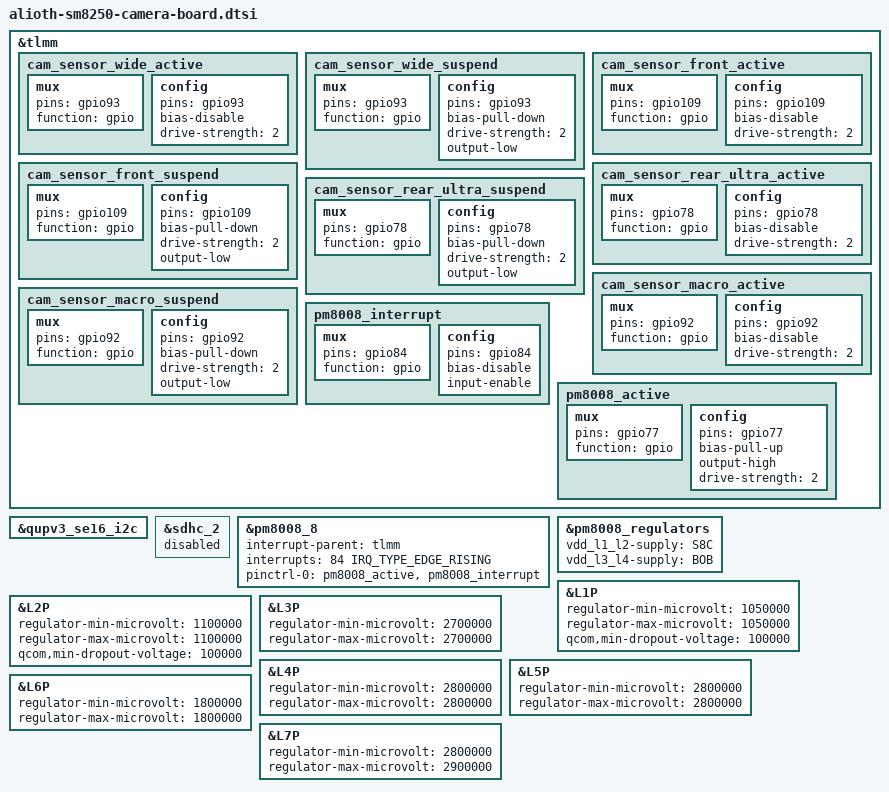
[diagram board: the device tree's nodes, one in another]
&tlmm {
	cam_sensor_wide_active: cam_sensor_wide_active {
		/* RESET WIDE */
		mux {
			pins = "gpio93";
			function = "gpio";
		};

		config {
			pins = "gpio93";
			bias-disable; /* No PULL */
			drive-strength = <2>; /* 2 MA */
		};
	};
	cam_sensor_wide_suspend: cam_sensor_wide_suspend {
		mux {
			pins = "gpio93";
			function = "gpio";
		};

		config {
			pins = "gpio93";
			bias-pull-down; /* PULL DOWN */
			drive-strength = <2>; /* 2 MA */
			output-low;
		};
	};
	cam_sensor_front_active: cam_sensor_front_active {
		/* RESET FRONT */
		mux {
			pins = "gpio109";
			function = "gpio";
		};

		config {
			pins = "gpio109";
			bias-disable; /* No PULL */
			drive-strength = <2>; /* 2 MA */
		};
	};
	cam_sensor_front_suspend: cam_sensor_front_suspend {
		mux {
			pins = "gpio109";
			function = "gpio";
		};

		config {
			pins = "gpio109";
			bias-pull-down; /* PULL DOWN */
			drive-strength = <2>; /* 2 MA */
			output-low;
		};
	};
	cam_sensor_rear_ultra_active: cam_sensor_rear_ultra_active {
		/* RESET REAR ULTRA */
		mux {
			pins = "gpio78";
			function = "gpio";
		};

		config {
			pins = "gpio78";
			bias-disable; /* No PULL */
			drive-strength = <2>; /* 2 MA */
		};
	};
	cam_sensor_rear_ultra_suspend: cam_sensor_rear_ultra_suspend {
		mux {
			pins = "gpio78";
			function = "gpio";
		};

		config {
			pins = "gpio78";
			bias-pull-down; /* PULL DOWN */
			drive-strength = <2>; /* 2 MA */
			output-low;
		};
	};
	cam_sensor_macro_active: cam_sensor_macro_active {
		/* RESET MACRO */
		mux {
			pins = "gpio92";
			function = "gpio";
		};

		config {
			pins = "gpio92";
			bias-disable; /* No PULL */
			drive-strength = <2>; /* 2 MA */
		};
	};
	cam_sensor_macro_suspend: cam_sensor_macro_suspend {
		mux {
			pins = "gpio92";
			function = "gpio";
		};

		config {
			pins = "gpio92";
			bias-pull-down; /* PULL DOWN */
			drive-strength = <2>; /* 2 MA */
			output-low;
		};
	};
};

&tlmm{
	pm8008_interrupt: pm8008_interrupt {
		mux {
			pins = "gpio84";
			function = "gpio";
		};

		config {
			pins = "gpio84";
			bias-disable;
			input-enable;
		};
	};

	pm8008_active: pm8008_active {
		mux {
			pins = "gpio77";
			function = "gpio";
		};

		config {
			pins = "gpio77";
			bias-pull-up;
			output-high;
			drive-strength = <2>;
		};
	};
};

&qupv3_se16_i2c {
	status = "ok";
	#include "pm8008.dtsi"
};

&sdhc_2 {
	status = "disabled";
};
&pm8008_8 {
	/* PM8008 IRQ STAT */
	interrupt-parent = <&tlmm>;
	interrupts = <84 IRQ_TYPE_EDGE_RISING>;

	pinctrl-names = "default";
	pinctrl-0 = <&pm8008_active &pm8008_interrupt>;
};
&pm8008_regulators {
	vdd_l1_l2-supply = <&S8C>;
	vdd_l3_l4-supply = <&BOB>;
};
&L1P {
	regulator-min-microvolt = <1050000>;
	regulator-max-microvolt = <1050000>;
	qcom,min-dropout-voltage = <100000>;
};

&L2P {
	regulator-min-microvolt = <1100000>;
	regulator-max-microvolt = <1100000>;
	qcom,min-dropout-voltage = <100000>;
};

&L3P {
	regulator-min-microvolt = <2700000>;
	regulator-max-microvolt = <2700000>;
};

&L4P {
	regulator-min-microvolt = <2800000>;
	regulator-max-microvolt = <2800000>;
};

&L5P {
	regulator-min-microvolt = <2800000>;
	regulator-max-microvolt = <2800000>;
};

&L6P {
	regulator-min-microvolt = <1800000>;
	regulator-max-microvolt = <1800000>;
};

&L7P {
	regulator-min-microvolt = <2800000>;
	regulator-max-microvolt = <2900000>;
};

